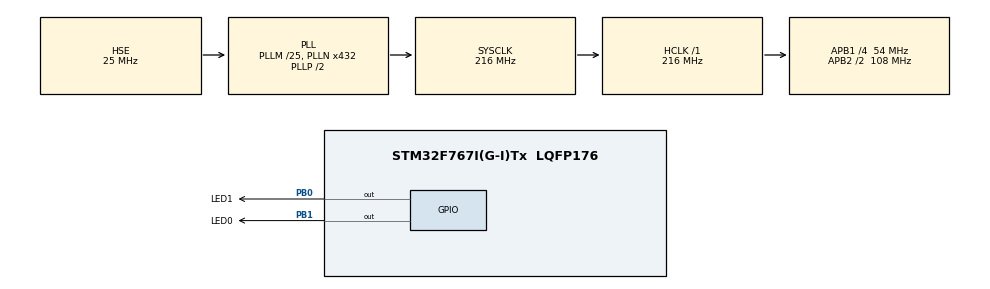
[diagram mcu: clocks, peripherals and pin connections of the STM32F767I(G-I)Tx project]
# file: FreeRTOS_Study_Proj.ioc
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CORTEX_M7.CPU_DCache=Enabled
CORTEX_M7.CPU_ICache=Enabled
CORTEX_M7.PREFETCH_ENABLE=1
FREERTOS.Tasks01=defaultTask,0,128,StartDefaultTask,Default,NULL,Dynamic,NULL,NULL;myTask02,-2,128,StartTask02,Default,NULL,Dynamic,NULL,NULL
FREERTOS.configCHECK_FOR_STACK_OVERFLOW=1
Mcu.Family=STM32F7
Mcu.Name=STM32F767I(G-I)Tx
Mcu.Package=LQFP176
NVIC.PriorityGroup=NVIC_PRIORITYGROUP_4
PB0.GPIO_Label=LED1
PB0.GPIO_Speed=GPIO_SPEED_FREQ_MEDIUM
PB0.PinState=GPIO_PIN_SET
PB0.Signal=GPIO_Output
PB1.GPIO_Label=LED0
PB1.GPIO_Speed=GPIO_SPEED_FREQ_MEDIUM
PB1.PinState=GPIO_PIN_SET
PB1.Signal=GPIO_Output
PH0/OSC_IN.Mode=HSE-External-Oscillator
PH0/OSC_IN.Signal=RCC_OSC_IN
PH1/OSC_OUT.Mode=HSE-External-Oscillator
PH1/OSC_OUT.Signal=RCC_OSC_OUT
ProjectManager.HeapSize=0x200
ProjectManager.StackSize=0x400
ProjectManager.TargetToolchain=MDK-ARM V5.32
RCC.AHBFreq_Value=216000000
RCC.APB1CLKDivider=RCC_HCLK_DIV4
RCC.APB1Freq_Value=54000000
RCC.APB1TimFreq_Value=108000000
RCC.APB2CLKDivider=RCC_HCLK_DIV2
RCC.APB2Freq_Value=108000000
RCC.APB2TimFreq_Value=216000000
RCC.CortexFreq_Value=216000000
RCC.HCLKFreq_Value=216000000
RCC.HSE_VALUE=25000000
RCC.HSI_VALUE=16000000
RCC.LSE_VALUE=32768
RCC.PLLM=25
RCC.PLLN=432
RCC.PLLSourceVirtual=RCC_PLLSOURCE_HSE
RCC.SYSCLKFreq_VALUE=216000000
RCC.SYSCLKSource=RCC_SYSCLKSOURCE_PLLCLK
RCC.USBFreq_Value=216000000
RCC.VCOOutputFreq_Value=432000000
VP_FREERTOS_VS_CMSIS_V1.Mode=CMSIS_V1
board=custom

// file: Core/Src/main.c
/* USER CODE BEGIN Header */
/**
  ******************************************************************************
  * @file           : main.c
  * @brief          : Main program body
  ******************************************************************************
  * @attention
  *
  * Copyright (c) 2022 STMicroelectronics.
  * All rights reserved.
  *
  * This software is licensed under terms that can be found in the LICENSE file
  * in the root directory of this software component.
  * If no LICENSE file comes with this software, it is provided AS-IS.
  *
  ******************************************************************************
  */
/* USER CODE END Header */
#include "main.h"
#include "cmsis_os.h"
#include "gpio.h"

/* USER CODE BEGIN Includes */

#include "stdio.h"

/* USER CODE END Includes */

void SystemClock_Config(void);
void MX_FREERTOS_Init(void);

int main(void)
{

  /* Enable I-Cache---------------------------------------------------------*/
  SCB_EnableICache();

  /* Enable D-Cache---------------------------------------------------------*/
  SCB_EnableDCache();

  /* MCU Configuration--------------------------------------------------------*/

  /* Reset of all peripherals, Initializes the Flash interface and the Systick. */
  HAL_Init();

  /* Configure the system clock */
  SystemClock_Config();

  /* Initialize all configured peripherals */
  MX_GPIO_Init();

  /* Call init function for freertos objects (in freertos.c) */
  MX_FREERTOS_Init();
  /* Start scheduler */
  osKernelStart();

  /* We should never get here as control is now taken by the scheduler */
  /* Infinite loop */
  while (1)
  {

  }
}

void SystemClock_Config(void)
{
  RCC_OscInitTypeDef RCC_OscInitStruct = {0};
  RCC_ClkInitTypeDef RCC_ClkInitStruct = {0};

  /** Configure the main internal regulator output voltage
  */
  __HAL_RCC_PWR_CLK_ENABLE();
  __HAL_PWR_VOLTAGESCALING_CONFIG(PWR_REGULATOR_VOLTAGE_SCALE1);
  /** Initializes the RCC Oscillators according to the specified parameters
  * in the RCC_OscInitTypeDef structure.
  */
  RCC_OscInitStruct.OscillatorType = RCC_OSCILLATORTYPE_HSE;
  RCC_OscInitStruct.HSEState = RCC_HSE_ON;
  RCC_OscInitStruct.PLL.PLLState = RCC_PLL_ON;
  RCC_OscInitStruct.PLL.PLLSource = RCC_PLLSOURCE_HSE;
  RCC_OscInitStruct.PLL.PLLM = 25;
  RCC_OscInitStruct.PLL.PLLN = 432;
  RCC_OscInitStruct.PLL.PLLP = RCC_PLLP_DIV2;
  RCC_OscInitStruct.PLL.PLLQ = 2;
  RCC_OscInitStruct.PLL.PLLR = 2;
  if (HAL_RCC_OscConfig(&RCC_OscInitStruct) != HAL_OK)
  {
    Error_Handler();
  }
  /** Activate the Over-Drive mode
  */
  if (HAL_PWREx_EnableOverDrive() != HAL_OK)
  {
    Error_Handler();
  }
  /** Initializes the CPU, AHB and APB buses clocks
  */
  RCC_ClkInitStruct.ClockType = RCC_CLOCKTYPE_HCLK|RCC_CLOCKTYPE_SYSCLK
                              |RCC_CLOCKTYPE_PCLK1|RCC_CLOCKTYPE_PCLK2;
  RCC_ClkInitStruct.SYSCLKSource = RCC_SYSCLKSOURCE_PLLCLK;
  RCC_ClkInitStruct.AHBCLKDivider = RCC_SYSCLK_DIV1;
  RCC_ClkInitStruct.APB1CLKDivider = RCC_HCLK_DIV4;
  RCC_ClkInitStruct.APB2CLKDivider = RCC_HCLK_DIV2;

  if (HAL_RCC_ClockConfig(&RCC_ClkInitStruct, FLASH_LATENCY_7) != HAL_OK)
  {
    Error_Handler();
  }
}

/* USER CODE BEGIN 4 */

int fputc(int ch, FILE *f)
{
	ITM_SendChar(ch);
	return ch;
}

/* USER CODE END 4 */

void Error_Handler(void)
{
  __disable_irq();
  while (1)
  {
  }
}

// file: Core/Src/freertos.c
/* USER CODE BEGIN Header */
/**
  ******************************************************************************
  * File Name          : freertos.c
  * Description        : Code for freertos applications
  ******************************************************************************
  * @attention
  *
  * Copyright (c) 2022 STMicroelectronics.
  * All rights reserved.
  *
  * This software is licensed under terms that can be found in the LICENSE file
  * in the root directory of this software component.
  * If no LICENSE file comes with this software, it is provided AS-IS.
  *
  ******************************************************************************
  */
/* USER CODE END Header */

#include "FreeRTOS.h"
#include "task.h"
#include "main.h"
#include "cmsis_os.h"

/* USER CODE BEGIN Variables */

osThreadId testTaskHandle;

/* USER CODE END Variables */
osThreadId defaultTaskHandle;
osThreadId myTask02Handle;

/* USER CODE BEGIN FunctionPrototypes */

void test_task_function(void const * argument);

/* USER CODE END FunctionPrototypes */

void StartDefaultTask(void const * argument);
void StartTask02(void const * argument);

void MX_FREERTOS_Init(void); /* (MISRA C 2004 rule 8.1) */

/* GetIdleTaskMemory prototype (linked to static allocation support) */
void vApplicationGetIdleTaskMemory( StaticTask_t **ppxIdleTaskTCBBuffer, StackType_t **ppxIdleTaskStackBuffer, uint32_t *pulIdleTaskStackSize );

/* Hook prototypes */
void vApplicationStackOverflowHook(xTaskHandle xTask, signed char *pcTaskName);

/* USER CODE BEGIN 4 */
__weak void vApplicationStackOverflowHook(xTaskHandle xTask, signed char *pcTaskName)
{
   /* Run time stack overflow checking is performed if
   configCHECK_FOR_STACK_OVERFLOW is defined to 1 or 2. This hook function is
   called if a stack overflow is detected. */
}
/* USER CODE END 4 */

/* USER CODE BEGIN GET_IDLE_TASK_MEMORY */
static StaticTask_t xIdleTaskTCBBuffer;
static StackType_t xIdleStack[configMINIMAL_STACK_SIZE];

void vApplicationGetIdleTaskMemory( StaticTask_t **ppxIdleTaskTCBBuffer, StackType_t **ppxIdleTaskStackBuffer, uint32_t *pulIdleTaskStackSize )
{
  *ppxIdleTaskTCBBuffer = &xIdleTaskTCBBuffer;
  *ppxIdleTaskStackBuffer = &xIdleStack[0];
  *pulIdleTaskStackSize = configMINIMAL_STACK_SIZE;
  /* place for user code */
}
/* USER CODE END GET_IDLE_TASK_MEMORY */

void MX_FREERTOS_Init(void) {

  /* Create the thread(s) */
  /* definition and creation of defaultTask */
  osThreadDef(defaultTask, StartDefaultTask, osPriorityNormal, 0, 128);
  defaultTaskHandle = osThreadCreate(osThread(defaultTask), NULL);

  /* definition and creation of myTask02 */
  osThreadDef(myTask02, StartTask02, osPriorityLow, 0, 128);
  myTask02Handle = osThreadCreate(osThread(myTask02), NULL);

  /* USER CODE BEGIN RTOS_THREADS */
  /* add threads, ... */
  osThreadDef(test_task, test_task_function, osPriorityBelowNormal, 0, 128);
	testTaskHandle = osThreadCreate(osThread(test_task), NULL);

  /* USER CODE END RTOS_THREADS */

}

void StartDefaultTask(void const * argument)
{
  for(;;)
  {
    osDelay(1);
  }
}

void StartTask02(void const * argument)
{
  /* USER CODE BEGIN StartTask02 */
  /* Infinite loop */
  for(;;)
  {
		HAL_GPIO_TogglePin(LED1_GPIO_Port, LED1_Pin);
//		HAL_GPIO_TogglePin(LED0_GPIO_Port, LED0_Pin);
    osDelay(500);
  }
  /* USER CODE END StartTask02 */
}

/* USER CODE BEGIN Application */

void test_task_function(void const * argument)
{
	static double float_num = 0.00;
  /* Infinite loop */
  for(;;)
  {
		float_num += 0.01f;
		printf("float_num value is: %.4f\r\n", float_num);
    osDelay(1000);
  }
}

/* USER CODE END Application */
